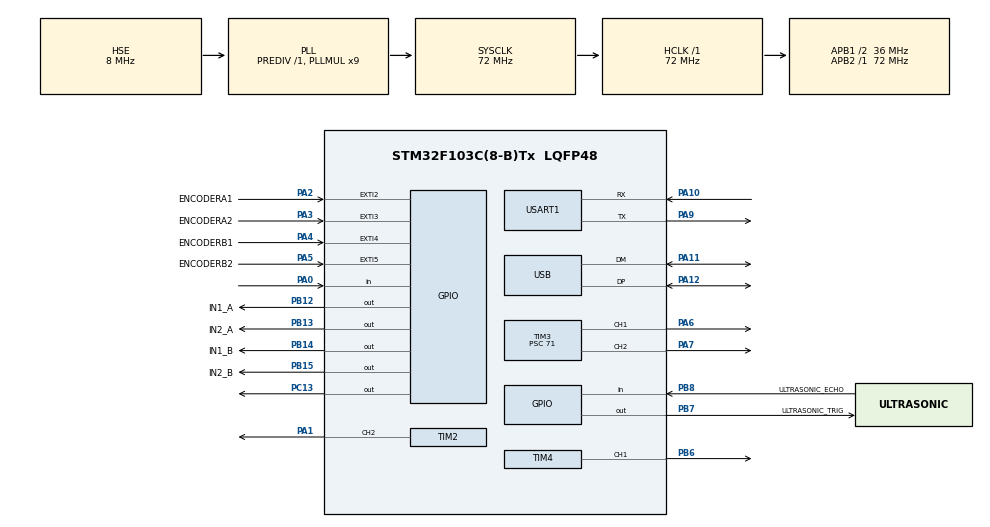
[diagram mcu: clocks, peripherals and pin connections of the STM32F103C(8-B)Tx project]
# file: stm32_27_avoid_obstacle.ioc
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Mcu.Family=STM32F1
Mcu.Name=STM32F103C(8-B)Tx
Mcu.Package=LQFP48
NVIC.EXTI2_IRQn=true\:0\:0\:false\:false\:true\:true\:true\:true
NVIC.EXTI3_IRQn=true\:0\:0\:false\:false\:true\:true\:true\:true
NVIC.EXTI4_IRQn=true\:0\:0\:false\:false\:true\:true\:true\:true
NVIC.EXTI9_5_IRQn=true\:0\:0\:false\:false\:true\:true\:true\:true
NVIC.PriorityGroup=NVIC_PRIORITYGROUP_4
NVIC.TIM1_UP_IRQn=true\:0\:0\:false\:false\:true\:true\:true\:true
NVIC.USART1_IRQn=true\:0\:0\:false\:false\:true\:true\:true\:true
NVIC.USB_LP_CAN1_RX0_IRQn=true\:0\:0\:false\:false\:true\:false\:true\:true
PA0-WKUP.GPIO_PuPd=GPIO_PULLUP
PA0-WKUP.Signal=GPIO_Input
PA1.Signal=S_TIM2_CH2
PA10.Mode=Asynchronous
PA10.Signal=USART1_RX
PA11.Mode=Device
PA11.Signal=USB_DM
PA12.Mode=Device
PA12.Signal=USB_DP
PA13.Mode=Serial_Wire
PA13.Signal=SYS_JTMS-SWDIO
PA14.Mode=Serial_Wire
PA14.Signal=SYS_JTCK-SWCLK
PA2.GPIO_Label=ENCODERA1
PA2.GPIO_ModeDefaultEXTI=GPIO_MODE_IT_RISING_FALLING
PA2.GPIO_PuPd=GPIO_PULLUP
PA2.Signal=GPXTI2
PA3.GPIO_Label=ENCODERA2
PA3.GPIO_ModeDefaultEXTI=GPIO_MODE_IT_RISING_FALLING
PA3.GPIO_PuPd=GPIO_PULLUP
PA3.Signal=GPXTI3
PA4.GPIO_Label=ENCODERB1
PA4.GPIO_ModeDefaultEXTI=GPIO_MODE_IT_RISING_FALLING
PA4.GPIO_PuPd=GPIO_PULLUP
PA4.Signal=GPXTI4
PA5.GPIO_Label=ENCODERB2
PA5.GPIO_ModeDefaultEXTI=GPIO_MODE_IT_RISING_FALLING
PA5.GPIO_PuPd=GPIO_PULLUP
PA5.Signal=GPXTI5
PA6.Signal=S_TIM3_CH1
PA7.Signal=S_TIM3_CH2
PA9.Mode=Asynchronous
PA9.Signal=USART1_TX
PB12.GPIO_Label=IN1_A
PB12.Signal=GPIO_Output
PB13.GPIO_Label=IN2_A
PB13.Signal=GPIO_Output
PB14.GPIO_Label=IN1_B
PB14.Signal=GPIO_Output
PB15.GPIO_Label=IN2_B
PB15.Signal=GPIO_Output
PB6.Signal=S_TIM4_CH1
PB7.GPIO_Label=ULTRASONIC_TRIG
PB7.Signal=GPIO_Output
PB8.GPIO_Label=ULTRASONIC_ECHO
PB8.Signal=GPIO_Input
PC13-TAMPER-RTC.GPIO_ModeDefaultOutputPP=GPIO_MODE_OUTPUT_OD
PC13-TAMPER-RTC.GPIO_PuPd=GPIO_NOPULL
PC13-TAMPER-RTC.PinState=GPIO_PIN_SET
PC13-TAMPER-RTC.Signal=GPIO_Output
PD0-OSC_IN.Mode=HSE-External-Oscillator
PD0-OSC_IN.Signal=RCC_OSC_IN
PD1-OSC_OUT.Mode=HSE-External-Oscillator
PD1-OSC_OUT.Signal=RCC_OSC_OUT
ProjectManager.HeapSize=0x200
ProjectManager.StackSize=0x400
ProjectManager.TargetToolchain=CMake
RCC.AHBFreq_Value=72000000
RCC.APB1CLKDivider=RCC_HCLK_DIV2
RCC.APB1Freq_Value=36000000
RCC.APB1TimFreq_Value=72000000
RCC.APB2Freq_Value=72000000
RCC.APB2TimFreq_Value=72000000
RCC.HCLKFreq_Value=72000000
RCC.PLLMUL=RCC_PLL_MUL9
RCC.SYSCLKFreq_VALUE=72000000
RCC.SYSCLKSource=RCC_SYSCLKSOURCE_PLLCLK
RCC.USBFreq_Value=48000000
RCC.USBPrescaler=RCC_USBCLKSOURCE_PLL_DIV1_5
SH.S_TIM2_CH2.0=TIM2_CH2,PWM Generation2 CH2
SH.S_TIM3_CH1.0=TIM3_CH1,PWM Generation1 CH1
SH.S_TIM3_CH2.0=TIM3_CH2,PWM Generation2 CH2
SH.S_TIM4_CH1.0=TIM4_CH1,PWM Generation1 CH1
TIM1.Period=10000-1
TIM1.Prescaler=72-1
TIM2.Channel-PWM\ Generation2\ CH2=TIM_CHANNEL_2
TIM2.Period=1000
TIM2.Prescaler=71
TIM3.Channel-PWM\ Generation1\ CH1=TIM_CHANNEL_1
TIM3.Channel-PWM\ Generation2\ CH2=TIM_CHANNEL_2
TIM3.Period=1000
TIM3.Prescaler=71
TIM4.Channel-PWM\ Generation1\ CH1=TIM_CHANNEL_1
TIM4.Period=20000-1
TIM4.Prescaler=72-1
USART1.VirtualMode=VM_ASYNC
USB_DEVICE.CLASS_NAME_FS=CDC
USB_DEVICE.VirtualMode=Cdc
USB_DEVICE.VirtualModeFS=Cdc_FS
VP_TIM1_VS_ClockSourceINT.Mode=Internal
VP_USB_DEVICE_VS_USB_DEVICE_CDC_FS.Mode=CDC_FS
board=custom

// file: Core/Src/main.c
/* USER CODE BEGIN Header */
/**
  ******************************************************************************
  * @file           : main.c
  * @brief          : Main program body
  ******************************************************************************
  * @attention
  *
  * Copyright (c) 2026 STMicroelectronics.
  * All rights reserved.
  *
  * This software is licensed under terms that can be found in the LICENSE file
  * in the root directory of this software component.
  * If no LICENSE file comes with this software, it is provided AS-IS.
  *
  ******************************************************************************
  */
/* USER CODE END Header */
#include "main.h"
#include "usb_device.h"

/* USER CODE BEGIN Includes */
#include "chapter-2.h"   /* 第 2 章：程序入口 chapter_main()（其内部调用第 1 章的函数库） */
/* USER CODE END Includes */

TIM_HandleTypeDef htim1;
TIM_HandleTypeDef htim2;
TIM_HandleTypeDef htim3;
TIM_HandleTypeDef htim4;

UART_HandleTypeDef huart1;

void SystemClock_Config(void);
static void MX_GPIO_Init(void);
static void MX_TIM2_Init(void);
static void MX_TIM3_Init(void);
static void MX_USART1_UART_Init(void);
static void MX_TIM1_Init(void);
static void MX_TIM4_Init(void);

int main(void)
{

  /* MCU Configuration--------------------------------------------------------*/

  /* Reset of all peripherals, Initializes the Flash interface and the Systick. */
  HAL_Init();

  /* Configure the system clock */
  SystemClock_Config();

  /* Initialize all configured peripherals */
  MX_GPIO_Init();
  MX_TIM2_Init();
  MX_USB_DEVICE_Init();
  MX_TIM3_Init();
  MX_USART1_UART_Init();
  MX_TIM1_Init();
  MX_TIM4_Init();
  /* USER CODE BEGIN 2 */
  chapter_main();
  /* USER CODE END 2 */

  /* Infinite loop */
  while (1)
  {

  }
}

void SystemClock_Config(void)
{
  RCC_OscInitTypeDef RCC_OscInitStruct = {0};
  RCC_ClkInitTypeDef RCC_ClkInitStruct = {0};
  RCC_PeriphCLKInitTypeDef PeriphClkInit = {0};

  /** Initializes the RCC Oscillators according to the specified parameters
  * in the RCC_OscInitTypeDef structure.
  */
  RCC_OscInitStruct.OscillatorType = RCC_OSCILLATORTYPE_HSE;
  RCC_OscInitStruct.HSEState = RCC_HSE_ON;
  RCC_OscInitStruct.HSEPredivValue = RCC_HSE_PREDIV_DIV1;
  RCC_OscInitStruct.HSIState = RCC_HSI_ON;
  RCC_OscInitStruct.PLL.PLLState = RCC_PLL_ON;
  RCC_OscInitStruct.PLL.PLLSource = RCC_PLLSOURCE_HSE;
  RCC_OscInitStruct.PLL.PLLMUL = RCC_PLL_MUL9;
  if (HAL_RCC_OscConfig(&RCC_OscInitStruct) != HAL_OK)
  {
    Error_Handler();
  }

  /** Initializes the CPU, AHB and APB buses clocks
  */
  RCC_ClkInitStruct.ClockType = RCC_CLOCKTYPE_HCLK|RCC_CLOCKTYPE_SYSCLK
                              |RCC_CLOCKTYPE_PCLK1|RCC_CLOCKTYPE_PCLK2;
  RCC_ClkInitStruct.SYSCLKSource = RCC_SYSCLKSOURCE_PLLCLK;
  RCC_ClkInitStruct.AHBCLKDivider = RCC_SYSCLK_DIV1;
  RCC_ClkInitStruct.APB1CLKDivider = RCC_HCLK_DIV2;
  RCC_ClkInitStruct.APB2CLKDivider = RCC_HCLK_DIV1;

  if (HAL_RCC_ClockConfig(&RCC_ClkInitStruct, FLASH_LATENCY_2) != HAL_OK)
  {
    Error_Handler();
  }
  PeriphClkInit.PeriphClockSelection = RCC_PERIPHCLK_USB;
  PeriphClkInit.UsbClockSelection = RCC_USBCLKSOURCE_PLL_DIV1_5;
  if (HAL_RCCEx_PeriphCLKConfig(&PeriphClkInit) != HAL_OK)
  {
    Error_Handler();
  }
}

static void MX_TIM1_Init(void)
{

  TIM_ClockConfigTypeDef sClockSourceConfig = {0};
  TIM_MasterConfigTypeDef sMasterConfig = {0};

  htim1.Instance = TIM1;
  htim1.Init.Prescaler = 72-1;
  htim1.Init.CounterMode = TIM_COUNTERMODE_UP;
  htim1.Init.Period = 10000-1;
  htim1.Init.ClockDivision = TIM_CLOCKDIVISION_DIV1;
  htim1.Init.RepetitionCounter = 0;
  htim1.Init.AutoReloadPreload = TIM_AUTORELOAD_PRELOAD_DISABLE;
  if (HAL_TIM_Base_Init(&htim1) != HAL_OK)
  {
    Error_Handler();
  }
  sClockSourceConfig.ClockSource = TIM_CLOCKSOURCE_INTERNAL;
  if (HAL_TIM_ConfigClockSource(&htim1, &sClockSourceConfig) != HAL_OK)
  {
    Error_Handler();
  }
  sMasterConfig.MasterOutputTrigger = TIM_TRGO_RESET;
  sMasterConfig.MasterSlaveMode = TIM_MASTERSLAVEMODE_DISABLE;
  if (HAL_TIMEx_MasterConfigSynchronization(&htim1, &sMasterConfig) != HAL_OK)
  {
    Error_Handler();
  }

}

static void MX_TIM2_Init(void)
{

  TIM_MasterConfigTypeDef sMasterConfig = {0};
  TIM_OC_InitTypeDef sConfigOC = {0};

  htim2.Instance = TIM2;
  htim2.Init.Prescaler = 71;
  htim2.Init.CounterMode = TIM_COUNTERMODE_UP;
  htim2.Init.Period = 1000;
  htim2.Init.ClockDivision = TIM_CLOCKDIVISION_DIV1;
  htim2.Init.AutoReloadPreload = TIM_AUTORELOAD_PRELOAD_DISABLE;
  if (HAL_TIM_PWM_Init(&htim2) != HAL_OK)
  {
    Error_Handler();
  }
  sMasterConfig.MasterOutputTrigger = TIM_TRGO_RESET;
  sMasterConfig.MasterSlaveMode = TIM_MASTERSLAVEMODE_DISABLE;
  if (HAL_TIMEx_MasterConfigSynchronization(&htim2, &sMasterConfig) != HAL_OK)
  {
    Error_Handler();
  }
  sConfigOC.OCMode = TIM_OCMODE_PWM1;
  sConfigOC.Pulse = 0;
  sConfigOC.OCPolarity = TIM_OCPOLARITY_HIGH;
  sConfigOC.OCFastMode = TIM_OCFAST_DISABLE;
  if (HAL_TIM_PWM_ConfigChannel(&htim2, &sConfigOC, TIM_CHANNEL_2) != HAL_OK)
  {
    Error_Handler();
  }
  HAL_TIM_MspPostInit(&htim2);

}

static void MX_TIM3_Init(void)
{

  TIM_MasterConfigTypeDef sMasterConfig = {0};
  TIM_OC_InitTypeDef sConfigOC = {0};

  htim3.Instance = TIM3;
  htim3.Init.Prescaler = 71;
  htim3.Init.CounterMode = TIM_COUNTERMODE_UP;
  htim3.Init.Period = 1000;
  htim3.Init.ClockDivision = TIM_CLOCKDIVISION_DIV1;
  htim3.Init.AutoReloadPreload = TIM_AUTORELOAD_PRELOAD_DISABLE;
  if (HAL_TIM_PWM_Init(&htim3) != HAL_OK)
  {
    Error_Handler();
  }
  sMasterConfig.MasterOutputTrigger = TIM_TRGO_RESET;
  sMasterConfig.MasterSlaveMode = TIM_MASTERSLAVEMODE_DISABLE;
  if (HAL_TIMEx_MasterConfigSynchronization(&htim3, &sMasterConfig) != HAL_OK)
  {
    Error_Handler();
  }
  sConfigOC.OCMode = TIM_OCMODE_PWM1;
  sConfigOC.Pulse = 0;
  sConfigOC.OCPolarity = TIM_OCPOLARITY_HIGH;
  sConfigOC.OCFastMode = TIM_OCFAST_DISABLE;
  if (HAL_TIM_PWM_ConfigChannel(&htim3, &sConfigOC, TIM_CHANNEL_1) != HAL_OK)
  {
    Error_Handler();
  }
  if (HAL_TIM_PWM_ConfigChannel(&htim3, &sConfigOC, TIM_CHANNEL_2) != HAL_OK)
  {
    Error_Handler();
  }
  HAL_TIM_MspPostInit(&htim3);

}

static void MX_TIM4_Init(void)
{

  TIM_MasterConfigTypeDef sMasterConfig = {0};
  TIM_OC_InitTypeDef sConfigOC = {0};

  htim4.Instance = TIM4;
  htim4.Init.Prescaler = 72-1;
  htim4.Init.CounterMode = TIM_COUNTERMODE_UP;
  htim4.Init.Period = 20000-1;
  htim4.Init.ClockDivision = TIM_CLOCKDIVISION_DIV1;
  htim4.Init.AutoReloadPreload = TIM_AUTORELOAD_PRELOAD_DISABLE;
  if (HAL_TIM_PWM_Init(&htim4) != HAL_OK)
  {
    Error_Handler();
  }
  sMasterConfig.MasterOutputTrigger = TIM_TRGO_RESET;
  sMasterConfig.MasterSlaveMode = TIM_MASTERSLAVEMODE_DISABLE;
  if (HAL_TIMEx_MasterConfigSynchronization(&htim4, &sMasterConfig) != HAL_OK)
  {
    Error_Handler();
  }
  sConfigOC.OCMode = TIM_OCMODE_PWM1;
  sConfigOC.Pulse = 0;
  sConfigOC.OCPolarity = TIM_OCPOLARITY_HIGH;
  sConfigOC.OCFastMode = TIM_OCFAST_DISABLE;
  if (HAL_TIM_PWM_ConfigChannel(&htim4, &sConfigOC, TIM_CHANNEL_1) != HAL_OK)
  {
    Error_Handler();
  }
  HAL_TIM_MspPostInit(&htim4);

}

static void MX_USART1_UART_Init(void)
{

  huart1.Instance = USART1;
  huart1.Init.BaudRate = 115200;
  huart1.Init.WordLength = UART_WORDLENGTH_8B;
  huart1.Init.StopBits = UART_STOPBITS_1;
  huart1.Init.Parity = UART_PARITY_NONE;
  huart1.Init.Mode = UART_MODE_TX_RX;
  huart1.Init.HwFlowCtl = UART_HWCONTROL_NONE;
  huart1.Init.OverSampling = UART_OVERSAMPLING_16;
  if (HAL_UART_Init(&huart1) != HAL_OK)
  {
    Error_Handler();
  }

}

static void MX_GPIO_Init(void)
{
  GPIO_InitTypeDef GPIO_InitStruct = {0};

  /* GPIO Ports Clock Enable */
  __HAL_RCC_GPIOC_CLK_ENABLE();
  __HAL_RCC_GPIOD_CLK_ENABLE();
  __HAL_RCC_GPIOA_CLK_ENABLE();
  __HAL_RCC_GPIOB_CLK_ENABLE();

  /*Configure GPIO pin Output Level */
  HAL_GPIO_WritePin(GPIOC, GPIO_PIN_13, GPIO_PIN_SET);

  /*Configure GPIO pin Output Level */
  HAL_GPIO_WritePin(GPIOB, IN1_A_Pin|IN2_A_Pin|IN1_B_Pin|IN2_B_Pin
                          |ULTRASONIC_TRIG_Pin, GPIO_PIN_RESET);

  /*Configure GPIO pin : PC13 */
  GPIO_InitStruct.Pin = GPIO_PIN_13;
  GPIO_InitStruct.Mode = GPIO_MODE_OUTPUT_OD;
  GPIO_InitStruct.Pull = GPIO_NOPULL;
  GPIO_InitStruct.Speed = GPIO_SPEED_FREQ_LOW;
  HAL_GPIO_Init(GPIOC, &GPIO_InitStruct);

  /*Configure GPIO pin : PA0 */
  GPIO_InitStruct.Pin = GPIO_PIN_0;
  GPIO_InitStruct.Mode = GPIO_MODE_INPUT;
  GPIO_InitStruct.Pull = GPIO_PULLUP;
  HAL_GPIO_Init(GPIOA, &GPIO_InitStruct);

  /*Configure GPIO pins : ENCODERA1_Pin ENCODERA2_Pin ENCODERB1_Pin ENCODERB2_Pin */
  GPIO_InitStruct.Pin = ENCODERA1_Pin|ENCODERA2_Pin|ENCODERB1_Pin|ENCODERB2_Pin;
  GPIO_InitStruct.Mode = GPIO_MODE_IT_RISING_FALLING;
  GPIO_InitStruct.Pull = GPIO_PULLUP;
  HAL_GPIO_Init(GPIOA, &GPIO_InitStruct);

  /*Configure GPIO pins : IN1_A_Pin IN2_A_Pin IN1_B_Pin IN2_B_Pin
                           ULTRASONIC_TRIG_Pin */
  GPIO_InitStruct.Pin = IN1_A_Pin|IN2_A_Pin|IN1_B_Pin|IN2_B_Pin
                          |ULTRASONIC_TRIG_Pin;
  GPIO_InitStruct.Mode = GPIO_MODE_OUTPUT_PP;
  GPIO_InitStruct.Pull = GPIO_NOPULL;
  GPIO_InitStruct.Speed = GPIO_SPEED_FREQ_LOW;
  HAL_GPIO_Init(GPIOB, &GPIO_InitStruct);

  /*Configure GPIO pin : ULTRASONIC_ECHO_Pin */
  GPIO_InitStruct.Pin = ULTRASONIC_ECHO_Pin;
  GPIO_InitStruct.Mode = GPIO_MODE_INPUT;
  GPIO_InitStruct.Pull = GPIO_NOPULL;
  HAL_GPIO_Init(ULTRASONIC_ECHO_GPIO_Port, &GPIO_InitStruct);

  /* EXTI interrupt init*/
  HAL_NVIC_SetPriority(EXTI2_IRQn, 0, 0);
  HAL_NVIC_EnableIRQ(EXTI2_IRQn);

  HAL_NVIC_SetPriority(EXTI3_IRQn, 0, 0);
  HAL_NVIC_EnableIRQ(EXTI3_IRQn);

  HAL_NVIC_SetPriority(EXTI4_IRQn, 0, 0);
  HAL_NVIC_EnableIRQ(EXTI4_IRQn);

  HAL_NVIC_SetPriority(EXTI9_5_IRQn, 0, 0);
  HAL_NVIC_EnableIRQ(EXTI9_5_IRQn);

}

void Error_Handler(void)
{
  __disable_irq();
  while (1)
  {
  }
}
